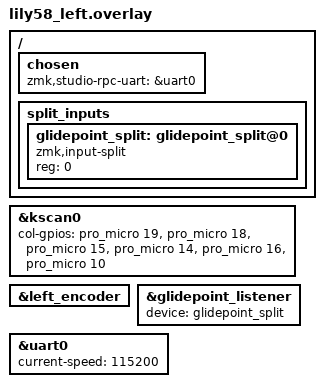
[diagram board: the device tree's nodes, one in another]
/*
 * Copyright (c) 2020 Pete Johanson
 *
 * SPDX-License-Identifier: MIT
 */

&kscan0 {
    col-gpios
        = <&pro_micro 19 GPIO_ACTIVE_HIGH>
        , <&pro_micro 18 GPIO_ACTIVE_HIGH>
        , <&pro_micro 15 GPIO_ACTIVE_HIGH>
        , <&pro_micro 14 GPIO_ACTIVE_HIGH>
        , <&pro_micro 16 GPIO_ACTIVE_HIGH>
        , <&pro_micro 10 GPIO_ACTIVE_HIGH>
        ;
};

&left_encoder {
    status = "okay";
};

/ {
    chosen {
        zmk,studio-rpc-uart = &uart0;
    };
};


&glidepoint_listener {
    status = "okay";
    device = <&glidepoint_split>;
};

/ {
    split_inputs {
        #address-cells = <1>;
        #size-cells = <0>;

        glidepoint_split: glidepoint_split@0 {
            compatible = "zmk,input-split";
            reg = <0>;
        };
    };
};

&uart0 {
    status = "okay";
    current-speed = <115200>;
};
